# ATBTLC1000WLCSP register map
Vendor: Atmel Corp; Series: SAMB11; File version: TODO
CPU: CM0 r0p0, little endian, no MPU, no FPU, 2 interrupt priority bits
Address unit: 32 bits
Registers are 32-bit, read-write, reset 0x0 unless marked. A register's access mark holds for its fields unless they carry their own. Offsets are from the block's base; [hi:lo] are bit positions.

## I2C0 — I2C Master/Slave Controller
Base 0x40003000
Same registers: I2C1 0x40003400
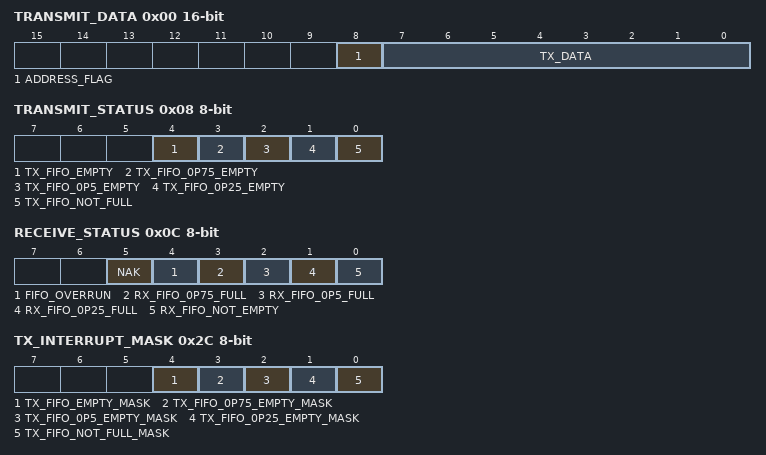
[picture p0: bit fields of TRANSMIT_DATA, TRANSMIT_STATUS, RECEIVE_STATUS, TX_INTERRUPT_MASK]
0x00 TRANSMIT_DATA 16-bit wo — Writes one byte to I2C Transmit Data FIFO.
  [8] ADDRESS_FLAG — Specifies that tx_data field is used for address and direction.
    0=tx_data field bits 7:0 are Transmit Data; 1=tx_data field bit 0 is direction (0: write to slave, 1: read from slave), and bits 7:1 are the Address to transmit
  [7:0] TX_DATA — Represents either Tx Data, or Address and Direction if address flag is set.
0x04 RECEIVE_DATA 8-bit ro — Read one byte from I2C Receive Data FIFO.
  [7:0] RX_BYTE — Oldest data in receive FIFO.
0x08 TRANSMIT_STATUS 8-bit ro — Status of the I2C transmitter. Each field can generate an interrupt if corresponding bit in the Tx interrupt mask register is set.
  [4] TX_FIFO_EMPTY — Active High indication when Tx FIFO is Empty and has no more character to transmit
  [3] TX_FIFO_0P75_EMPTY — Active High indication when Tx FIFO is at least three quarters empty. Reset when more.
  [2] TX_FIFO_0P5_EMPTY — Active High indication when Tx FIFO is at least half empty. Reset when more.
  [1] TX_FIFO_0P25_EMPTY — Active High indication when Tx FIFO is at least quarter empty. Reset when more.
  [0] TX_FIFO_NOT_FULL — Active High indication when Tx FIFO can still accepts at least one more character.
    0=TX FIFO Full; 1=TX FIFO not Full
0x0C RECEIVE_STATUS 8-bit ro — Status of the I2C receiver. Each field can generate an interrupt if corresponding bit in the Rx interrupt mask register is set.
  [5] NAK — Active High indication when NAK is received. The I2C module will retry transmission unless transaction aborted by the flush register.
  [4] FIFO_OVERRUN — Active High indication when character is received but FIFO is full. Reset by reading the status register.
  [3] RX_FIFO_0P75_FULL — Active High indication when FIFO is at least three quarters full. Reset when less.
  [2] RX_FIFO_0P5_FULL — Active High indication when FIFO is at least half full. Reset when less.
  [1] RX_FIFO_0P25_FULL — Active High indication when FIFO is at least quarter full. Reset when less.
  [0] RX_FIFO_NOT_EMPTY — Active High indication when data is available in Rx FIFO
0x10 CLOCK_SOURCE_SELECT 8-bit
  [1:0] CLOCK — Clock Used to Generate Divided Clock
    0=26 MHz Clock; 1=13 MHz Clock; 2=6.5 MHz Clock; 3=3.25 MHz Clock
0x14 I2C_MODULE_ENABLE 8-bit — I2C Enable
  [0] ENABLE — Enables I2C Operation
0x18 I2C_CLK_DIVIDER 16-bit — Register sets the divide ratio used to generate the sck clock from the module's input clock.
  [15:0] I2C_DIVIDE_RATIO — Clock Divide Ratio. The input clock signal is divided by (n+1) where n is the value set in this field. The minimum division is by 2; a value of 0 is illegal.
0x1C I2C_MASTER_MODE 8-bit — Selects I2C Master or Slave Mode.
  [0] MASTER_ENABLE — Active High I2C Master Mode Enable
    0=I2C Slave; 1=I2C Master
0x20 I2C_ONBUS 8-bit — Enable/Disable transactions when in Master Mode.
  [0] ONBUS_ENABLE — Active High Enable to initiate transactions when in Master Mode.
    0=Master completes current byte and generates stop condition on bus; 1=Master tranmits contents of FIFO until empty
0x24 I2C_SLAVE_ADDRESS 8-bit — Configures the I2C slave Address.
  [6:0] ADDRESS — I2C Slave Address
0x28 I2C_STATUS 8-bit ro — Status of I2C Module.
  [0] I2C_ACTIVE — Active High indicatation that the I2C Module is active. While set, I2C configuration should not be modified.
0x2C TX_INTERRUPT_MASK 8-bit — Enable or Disable the generation of interrupts by the tx_status register.
  [4] TX_FIFO_EMPTY_MASK — Active High Enable of tx_fifo_empty interrupt
  [3] TX_FIFO_0P75_EMPTY_MASK — Active High Enable of tx_fifo_0p75_empty interrupt
  [2] TX_FIFO_0P5_EMPTY_MASK — Active High Enable of tx_fifo_0p5_empty interrupt
  [1] TX_FIFO_0P25_EMPTY_MASK — Active High Enable of tx_fifo_0p25_empty interrupt
  [0] TX_FIFO_NOT_FULL_MASK — Active High Enable of tx_fifo_not_full interrupt
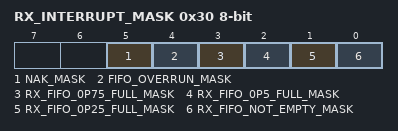
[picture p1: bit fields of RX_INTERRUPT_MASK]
0x30 RX_INTERRUPT_MASK 8-bit — Enable or Disable the generation of interrupts by the rx_status register.
  [5] NAK_MASK — Active High Enable NAK interrupt
  [4] FIFO_OVERRUN_MASK — Active High Enable of FIFO overrun interrupt
  [3] RX_FIFO_0P75_FULL_MASK — Active High Enable of rx_fifo_0p75_full interrupt
  [2] RX_FIFO_0P5_FULL_MASK — Active High Enable of rx_fifo_0p5_full interrupt
  [1] RX_FIFO_0P25_FULL_MASK — Active High Enable of rx_fifo_0p25_full interrupt
  [0] RX_FIFO_NOT_EMPTY_MASK — Active High Enable of rx_fifo_not_empty interrupt
0x34 I2C_FLUSH 8-bit wo (reset mask 0x1) — Writing to this address flushes the contents of both the Tx and Rx FIFOs. The value written has no effect. Flushing the Tx FIFO will abort ongoing transactions when the current byte has been transmitted.
